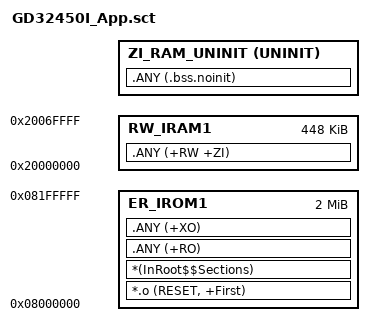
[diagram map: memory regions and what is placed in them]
; *************************************************************
; *** Scatter-Loading Description File generated by uVision ***
; *************************************************************

LR_IROM1 0x08000000 0x00200000  {    ; load region size_region (修改为从0x08000000开始)
  ER_IROM1 0x08000000 0x00200000  {  ; load address = execution address (修改为从0x08000000开始)
   *.o (RESET, +First)
   *(InRoot$$Sections)
   .ANY (+RO)
   .ANY (+XO)
  }
  RW_IRAM1 0x20000000 0x00070000  {  ; RW data
   .ANY (+RW +ZI)
  }
  ZI_RAM_UNINIT +0 UNINIT {
   .ANY (.bss.noinit)
  }
}

